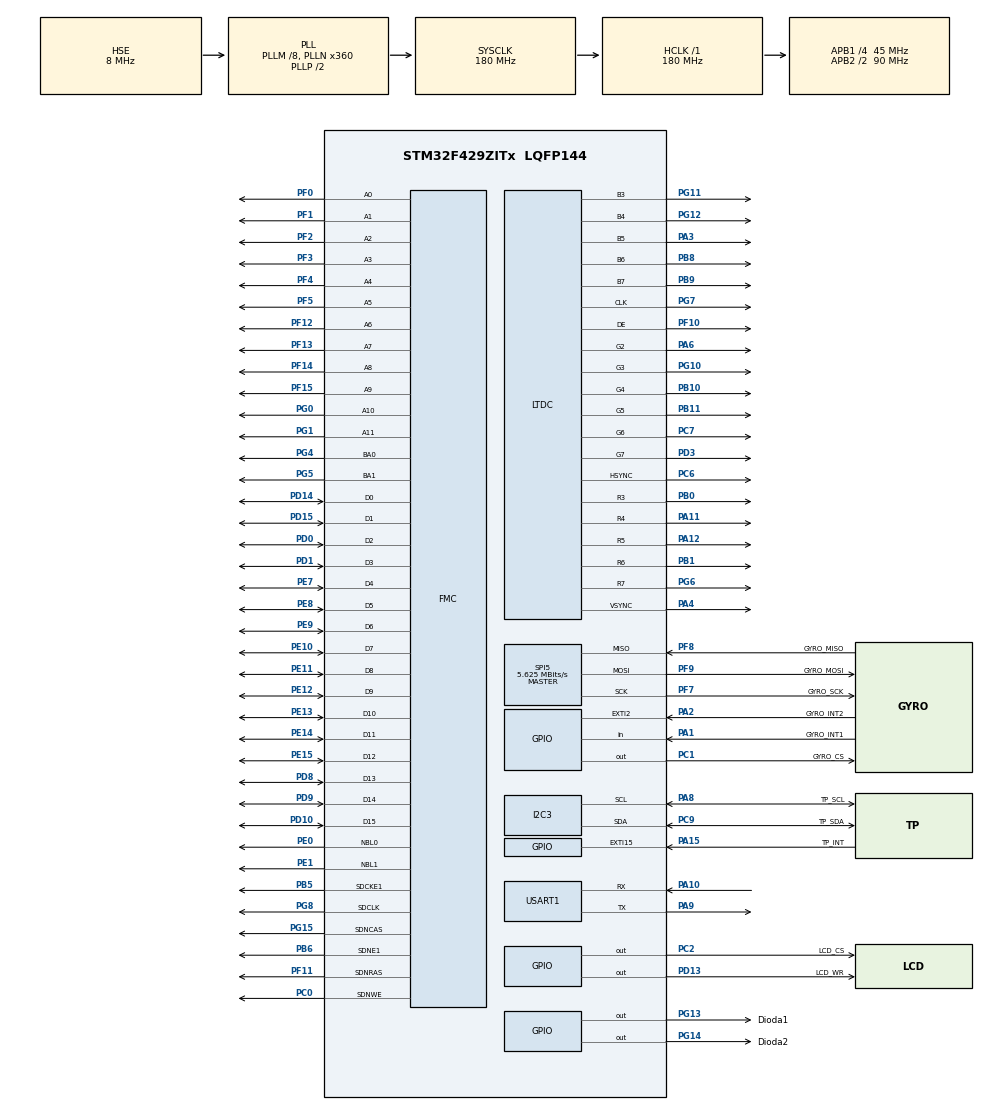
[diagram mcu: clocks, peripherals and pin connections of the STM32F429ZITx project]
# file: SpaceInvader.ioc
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DMA2D.ColorMode=DMA2D_OUTPUT_ARGB8888
DMA2D.Mode=DMA2D_R2M
FMC.CASLatency1=FMC_SDRAM_CAS_LATENCY_3
FMC.ExitSelfRefreshDelay1=7
FMC.LoadToActiveDelay1=2
FMC.RCDDelay1=2
FMC.RPDelay1=2
FMC.RPDelay2=2
FMC.ReadPipeDelay1=FMC_SDRAM_RPIPE_DELAY_1
FMC.ReadPipeDelay2=FMC_SDRAM_RPIPE_DELAY_1
FMC.RowCycleDelay1=7
FMC.RowCycleDelay2=7
FMC.SDClockPeriod1=FMC_SDRAM_CLOCK_PERIOD_2
FMC.SDClockPeriod2=FMC_SDRAM_CLOCK_PERIOD_2
FMC.SelfRefreshTime1=4
FMC.WriteRecoveryTime1=3
I2C3.I2C_Mode=I2C_Fast
LTDC.ActiveH=320
LTDC.ActiveW=240
LTDC.Alpha0_L0=0
LTDC.Alpha_L0=255
LTDC.BlendingFactor1_L0=LTDC_BLENDING_FACTOR1_PAxCA
LTDC.BlendingFactor2_L0=LTDC_BLENDING_FACTOR2_PAxCA
LTDC.FBStartAdress_L0=0xD0000000
LTDC.FBStartAdress_L1=0xD0006000
LTDC.HBP=20
LTDC.HFP=10
LTDC.HSync=10
LTDC.ImageHeight_L0=320
LTDC.ImageHeight_L1=320
LTDC.ImageWidth_L0=240
LTDC.ImageWidth_L1=240
LTDC.Layers=0
LTDC.PixelFormat_L0=LTDC_PIXEL_FORMAT_ARGB8888
LTDC.VFP=4
LTDC.VSync=2
LTDC.WindowX1_L0=240
LTDC.WindowX1_L1=240
LTDC.WindowY1_L0=320
LTDC.WindowY1_L1=320
Mcu.Family=STM32F4
Mcu.Name=STM32F429ZITx
Mcu.Package=LQFP144
NVIC.EXTI15_10_IRQn=true\:0\:0\:false\:false\:true\:true\:true\:true
NVIC.EXTI2_IRQn=true\:0\:0\:false\:false\:true\:true\:true\:true
NVIC.I2C3_ER_IRQn=true\:0\:0\:false\:false\:true\:true\:true\:true
NVIC.I2C3_EV_IRQn=true\:0\:0\:false\:false\:true\:true\:true\:true
NVIC.PriorityGroup=NVIC_PRIORITYGROUP_4
NVIC.TIM6_DAC_IRQn=true\:0\:0\:false\:false\:true\:true\:true\:true
NVIC.USART1_IRQn=true\:0\:0\:false\:false\:true\:true\:true\:true
PA1.GPIO_Label=GYRO_INT1
PA1.Signal=GPIO_Input
PA10.Mode=Asynchronous
PA10.Signal=USART1_RX
PA11.Mode=RGB565
PA11.Signal=LTDC_R4
PA12.Mode=RGB565
PA12.Signal=LTDC_R5
PA15.GPIO_Label=TP_INT
PA15.GPIO_ModeDefaultEXTI=GPIO_MODE_IT_FALLING
PA15.GPIO_PuPd=GPIO_PULLUP
PA15.Signal=GPXTI15
PA2.GPIO_Label=GYRO_INT2
PA2.GPIO_ModeDefaultEXTI=GPIO_MODE_IT_RISING_FALLING
PA2.Signal=GPXTI2
PA3.Mode=RGB565
PA3.Signal=LTDC_B5
PA4.Mode=RGB565
PA4.Signal=LTDC_VSYNC
PA6.Mode=RGB565
PA6.Signal=LTDC_G2
PA8.GPIO_Label=TP_SCL
PA8.Mode=I2C
PA8.Signal=I2C3_SCL
PA9.Mode=Asynchronous
PA9.Signal=USART1_TX
PB0.Mode=RGB565
PB0.Signal=LTDC_R3
PB1.Mode=RGB565
PB1.Signal=LTDC_R6
PB10.Mode=RGB565
PB10.Signal=LTDC_G4
PB11.Mode=RGB565
PB11.Signal=LTDC_G5
PB5.Mode=SdramChipSelect2_1
PB5.Signal=FMC_SDCKE1
PB6.Mode=SdramChipSelect2_1
PB6.Signal=FMC_SDNE1
PB8.Mode=RGB565
PB8.Signal=LTDC_B6
PB9.Mode=RGB565
PB9.Signal=LTDC_B7
PC0.Signal=FMC_SDNWE
PC1.GPIO_Label=GYRO_CS
PC1.PinState=GPIO_PIN_SET
PC1.Signal=GPIO_Output
PC14/OSC32_IN.GPIO_Label=OSC_IN
PC14/OSC32_IN.Signal=RCC_OSC32_IN
PC15/OSC32_OUT.GPIO_Label=OSC_OUT
PC15/OSC32_OUT.Signal=RCC_OSC32_OUT
PC2.GPIO_Label=LCD_CS
PC2.PinState=GPIO_PIN_SET
PC2.Signal=GPIO_Output
PC6.Mode=RGB565
PC6.Signal=LTDC_HSYNC
PC7.Mode=RGB565
PC7.Signal=LTDC_G6
PC9.GPIO_Label=TP_SDA
PC9.Mode=I2C
PC9.Signal=I2C3_SDA
PD0.Signal=FMC_D2_DA2
PD1.Signal=FMC_D3_DA3
PD10.Signal=FMC_D15_DA15
PD13.GPIO_Label=LCD_WR
PD13.Signal=GPIO_Output
PD14.Signal=FMC_D0_DA0
PD15.Signal=FMC_D1_DA1
PD3.Mode=RGB565
PD3.Signal=LTDC_G7
PD8.Signal=FMC_D13_DA13
PD9.Signal=FMC_D14_DA14
PE0.Signal=FMC_NBL0
PE1.Signal=FMC_NBL1
PE10.Signal=FMC_D7_DA7
PE11.Signal=FMC_D8_DA8
PE12.Signal=FMC_D9_DA9
PE13.Signal=FMC_D10_DA10
PE14.Signal=FMC_D11_DA11
PE15.Signal=FMC_D12_DA12
PE7.Signal=FMC_D4_DA4
PE8.Signal=FMC_D5_DA5
PE9.Signal=FMC_D6_DA6
PF0.Signal=FMC_A0
PF1.Signal=FMC_A1
PF10.Mode=RGB565
PF10.Signal=LTDC_DE
PF11.Signal=FMC_SDNRAS
PF12.Signal=FMC_A6
PF13.Signal=FMC_A7
PF14.Signal=FMC_A8
PF15.Signal=FMC_A9
PF2.Signal=FMC_A2
PF3.Signal=FMC_A3
PF4.Signal=FMC_A4
PF5.Signal=FMC_A5
PF7.GPIO_Label=GYRO_SCK
PF7.Mode=Full_Duplex_Master
PF7.Signal=SPI5_SCK
PF8.GPIO_Label=GYRO_MISO
PF8.Mode=Full_Duplex_Master
PF8.Signal=SPI5_MISO
PF9.GPIO_Label=GYRO_MOSI
PF9.Mode=Full_Duplex_Master
PF9.Signal=SPI5_MOSI
PG0.Signal=FMC_A10
PG1.Signal=FMC_A11
PG10.Mode=RGB565
PG10.Signal=LTDC_G3
PG11.Mode=RGB565
PG11.Signal=LTDC_B3
PG12.Mode=RGB565
PG12.Signal=LTDC_B4
PG13.GPIO_Label=Dioda1
PG13.Signal=GPIO_Output
PG14.GPIO_Label=Dioda2
PG14.Signal=GPIO_Output
PG15.Signal=FMC_SDNCAS
PG4.Signal=FMC_A14_BA0
PG5.Signal=FMC_A15_BA1
PG6.Mode=RGB565
PG6.Signal=LTDC_R7
PG7.Mode=RGB565
PG7.Signal=LTDC_CLK
PG8.Signal=FMC_SDCLK
PH0/OSC_IN.Mode=HSE-External-Oscillator
PH0/OSC_IN.Signal=RCC_OSC_IN
PH1/OSC_OUT.Mode=HSE-External-Oscillator
PH1/OSC_OUT.Signal=RCC_OSC_OUT
ProjectManager.HeapSize=0x200
ProjectManager.StackSize=0x400
ProjectManager.TargetToolchain=STM32CubeIDE
RCC.48MHZClocksFreq_Value=90000000
RCC.AHBFreq_Value=180000000
RCC.APB1CLKDivider=RCC_HCLK_DIV4
RCC.APB1Freq_Value=45000000
RCC.APB1TimFreq_Value=90000000
RCC.APB2CLKDivider=RCC_HCLK_DIV2
RCC.APB2Freq_Value=90000000
RCC.APB2TimFreq_Value=180000000
RCC.CortexFreq_Value=180000000
RCC.HCLKFreq_Value=180000000
RCC.HSE_VALUE=8000000
RCC.HSICalibrationValue=8
RCC.HSI_VALUE=16000000
RCC.LSE_VALUE=32768
RCC.PLLM=8
RCC.PLLN=360
RCC.PLLSAIDivR=RCC_PLLSAIDIVR_8
RCC.PLLSAIN=192
RCC.PLLSAIR=4
RCC.PLLSourceVirtual=RCC_PLLSOURCE_HSE
RCC.SYSCLKFreq_VALUE=180000000
RCC.SYSCLKSource=RCC_SYSCLKSOURCE_PLLCLK
RCC.VCOOutputFreq_Value=360000000
SH.FMC_A0.0=FMC_A0,12b-sda1
SH.FMC_A1.0=FMC_A1,12b-sda1
SH.FMC_A10.0=FMC_A10,12b-sda1
SH.FMC_A11.0=FMC_A11,12b-sda1
SH.FMC_A14_BA0.0=FMC_BA0,FourSdramBanks1
SH.FMC_A15_BA1.0=FMC_BA1,FourSdramBanks1
SH.FMC_A2.0=FMC_A2,12b-sda1
SH.FMC_A3.0=FMC_A3,12b-sda1
SH.FMC_A4.0=FMC_A4,12b-sda1
SH.FMC_A5.0=FMC_A5,12b-sda1
SH.FMC_A6.0=FMC_A6,12b-sda1
SH.FMC_A7.0=FMC_A7,12b-sda1
SH.FMC_A8.0=FMC_A8,12b-sda1
SH.FMC_A9.0=FMC_A9,12b-sda1
SH.FMC_D0_DA0.0=FMC_D0,sd-16b-d1
SH.FMC_D10_DA10.0=FMC_D10,sd-16b-d1
SH.FMC_D11_DA11.0=FMC_D11,sd-16b-d1
SH.FMC_D12_DA12.0=FMC_D12,sd-16b-d1
SH.FMC_D13_DA13.0=FMC_D13,sd-16b-d1
SH.FMC_D14_DA14.0=FMC_D14,sd-16b-d1
SH.FMC_D15_DA15.0=FMC_D15,sd-16b-d1
SH.FMC_D1_DA1.0=FMC_D1,sd-16b-d1
SH.FMC_D2_DA2.0=FMC_D2,sd-16b-d1
SH.FMC_D3_DA3.0=FMC_D3,sd-16b-d1
SH.FMC_D4_DA4.0=FMC_D4,sd-16b-d1
SH.FMC_D5_DA5.0=FMC_D5,sd-16b-d1
SH.FMC_D6_DA6.0=FMC_D6,sd-16b-d1
SH.FMC_D7_DA7.0=FMC_D7,sd-16b-d1
SH.FMC_D8_DA8.0=FMC_D8,sd-16b-d1
SH.FMC_D9_DA9.0=FMC_D9,sd-16b-d1
SH.FMC_NBL0.0=FMC_NBL0,Sd2ByteEnable1
SH.FMC_NBL1.0=FMC_NBL1,Sd2ByteEnable1
SH.FMC_SDCLK.0=FMC_SDCLK,12b-sda1
SH.FMC_SDNCAS.0=FMC_SDNCAS,12b-sda1
SH.FMC_SDNRAS.0=FMC_SDNRAS,12b-sda1
SH.FMC_SDNWE.0=FMC_SDNWE,12b-sda1
SPI5.BaudRatePrescaler=SPI_BAUDRATEPRESCALER_16
SPI5.CalculateBaudRate=5.625 MBits/s
SPI5.DataSize=SPI_DATASIZE_8BIT
SPI5.Direction=SPI_DIRECTION_2LINES
SPI5.Mode=SPI_MODE_MASTER
SPI5.VirtualType=VM_MASTER
TIM6.Period=99
TIM6.Prescaler=8999
USART1.VirtualMode=VM_ASYNC
VP_DMA2D_VS_DMA2D.Mode=DMA2D_Activate
VP_TIM6_VS_ClockSourceINT.Mode=Enable_Timer
board=custom

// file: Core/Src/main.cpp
/* USER CODE BEGIN Header */
/**
  ******************************************************************************
  * @file           : main.c
  * @brief          : Main program body
  ******************************************************************************
  * @attention
  *
  * Copyright (c) 2025 STMicroelectronics.
  * All rights reserved.
  *
  * This software is licensed under terms that can be found in the LICENSE file
  * in the root directory of this software component.
  * If no LICENSE file comes with this software, it is provided AS-IS.
  *
  ******************************************************************************
  */
/* USER CODE END Header */
#include <game_manager.hh>
extern "C"{
#include "main.h"
/* USER CODE BEGIN Includes */
#include "stdio.h"
#include "stdlib.h"
#include "drawFunctions.h"
#include "lcd.h"
#include "gyroscope.h"
#include "touch_panel.h"
#include "sram.h"
#include "gui.h"
/* USER CODE END Includes */

DMA2D_HandleTypeDef hdma2d;

I2C_HandleTypeDef hi2c3;

LTDC_HandleTypeDef hltdc;

SPI_HandleTypeDef hspi5;

TIM_HandleTypeDef htim6;

UART_HandleTypeDef huart1;

SDRAM_HandleTypeDef hsdram1;

/* USER CODE BEGIN PV */
uint32_t CURRENT_BUFFER=FRAMEBUFF_1;
uint32_t CURRENT_BUFFER_END=FRAMEBUFF_1_END;
uint32_t CURRENT_BACK_BUFFER=FRAMEBUFF_2;
uint32_t CURRENT_BACK_BUFFER_END=FRAMEBUFF_2_END;

bool textCenter=false;
volatile int TouchDetected=0;
volatile int RotDetected=0;
MenuState State=MENU;
int points=0;
int record=0;
bool isWon=false;
/* USER CODE END PV */

void SystemClock_Config(void);
static void MX_GPIO_Init(void);
static void MX_SPI5_Init(void);
static void MX_LTDC_Init(void);
static void MX_FMC_Init(void);
static void MX_DMA2D_Init(void);
static void MX_I2C3_Init(void);
static void MX_USART1_UART_Init(void);
static void MX_TIM6_Init(void);
/* USER CODE BEGIN PFP */
int _write(int, char *, int);
/* USER CODE END PFP */

/* USER CODE BEGIN 0 */
void HAL_GPIO_EXTI_Callback(uint16_t GPIO_Pin)
{
	if (GPIO_Pin == TP_INT_Pin)
	{
		TouchDetected=1;
	}
	if (GPIO_Pin == GYRO_INT2_Pin)
	{
		RotDetected=1;
	}
}
/* USER CODE END 0 */

/**
  * @brief  The application entry point.
  * @retval int
  */}
int main(void)
{

  /* MCU Configuration--------------------------------------------------------*/

  /* Reset of all peripherals, Initializes the Flash interface and the Systick. */
  HAL_Init();

  /* Configure the system clock */
  SystemClock_Config();

  /* Initialize all configured peripherals */
  MX_GPIO_Init();
  MX_SPI5_Init();
  MX_LTDC_Init();
  MX_FMC_Init();
  MX_DMA2D_Init();
  MX_I2C3_Init();
  MX_USART1_UART_Init();
  MX_TIM6_Init();
  /* USER CODE BEGIN 2 */
  initGyro();
  initTouchPanel();
  //testSDRAM();
  calibrateGyro();
  /* USER CODE END 2 */

  /* Infinite loop */
  /* USER CODE BEGIN WHILE */
  while(1)
  {
	  if(State==MENU) operateMenu();

	  srand(HAL_GetTick());
	  if(State==GAME) operateGame();

	  if(State==END) operateEndMenu();
    /* USER CODE END WHILE */

  }
}

extern "C"
{
void SystemClock_Config(void)
{
  RCC_OscInitTypeDef RCC_OscInitStruct = {0};
  RCC_ClkInitTypeDef RCC_ClkInitStruct = {0};

  /** Configure the main internal regulator output voltage
  */
  __HAL_RCC_PWR_CLK_ENABLE();
  __HAL_PWR_VOLTAGESCALING_CONFIG(PWR_REGULATOR_VOLTAGE_SCALE1);

  /** Initializes the RCC Oscillators according to the specified parameters
  * in the RCC_OscInitTypeDef structure.
  */
  RCC_OscInitStruct.OscillatorType = RCC_OSCILLATORTYPE_HSE;
  RCC_OscInitStruct.HSEState = RCC_HSE_ON;
  RCC_OscInitStruct.PLL.PLLState = RCC_PLL_ON;
  RCC_OscInitStruct.PLL.PLLSource = RCC_PLLSOURCE_HSE;
  RCC_OscInitStruct.PLL.PLLM = 8;
  RCC_OscInitStruct.PLL.PLLN = 360;
  RCC_OscInitStruct.PLL.PLLP = RCC_PLLP_DIV2;
  RCC_OscInitStruct.PLL.PLLQ = 4;
  if (HAL_RCC_OscConfig(&RCC_OscInitStruct) != HAL_OK)
  {
    Error_Handler();
  }

  /** Activate the Over-Drive mode
  */
  if (HAL_PWREx_EnableOverDrive() != HAL_OK)
  {
    Error_Handler();
  }

  /** Initializes the CPU, AHB and APB buses clocks
  */
  RCC_ClkInitStruct.ClockType = RCC_CLOCKTYPE_HCLK|RCC_CLOCKTYPE_SYSCLK
                              |RCC_CLOCKTYPE_PCLK1|RCC_CLOCKTYPE_PCLK2;
  RCC_ClkInitStruct.SYSCLKSource = RCC_SYSCLKSOURCE_PLLCLK;
  RCC_ClkInitStruct.AHBCLKDivider = RCC_SYSCLK_DIV1;
  RCC_ClkInitStruct.APB1CLKDivider = RCC_HCLK_DIV4;
  RCC_ClkInitStruct.APB2CLKDivider = RCC_HCLK_DIV2;

  if (HAL_RCC_ClockConfig(&RCC_ClkInitStruct, FLASH_LATENCY_5) != HAL_OK)
  {
    Error_Handler();
  }
}

static void MX_DMA2D_Init(void)
{

  hdma2d.Instance = DMA2D;
  hdma2d.Init.Mode = DMA2D_R2M;
  hdma2d.Init.ColorMode = DMA2D_OUTPUT_ARGB8888;
  hdma2d.Init.OutputOffset = 0;
  if (HAL_DMA2D_Init(&hdma2d) != HAL_OK)
  {
    Error_Handler();
  }
  /* USER CODE BEGIN DMA2D_Init 2 */
  // Konfiguracja warstwy tła
  hdma2d.LayerCfg[0].AlphaMode = DMA2D_NO_MODIF_ALPHA;
  hdma2d.LayerCfg[0].InputColorMode = DMA2D_INPUT_ARGB8888;
  HAL_DMA2D_ConfigLayer(&hdma2d, 0);
  // Konfiguracja warstwy ktora będzie nadpisywana z blendowaniem
  hdma2d.LayerCfg[1].AlphaMode = DMA2D_NO_MODIF_ALPHA;
  hdma2d.LayerCfg[1].InputColorMode = DMA2D_INPUT_ARGB8888;
  hdma2d.LayerCfg[1].InputOffset = 0;
  HAL_DMA2D_ConfigLayer(&hdma2d, 1);
  setBackgroundColor(0xFF000000);
  /* USER CODE END DMA2D_Init 2 */

}

static void MX_I2C3_Init(void)
{

  hi2c3.Instance = I2C3;
  hi2c3.Init.ClockSpeed = 400000;
  hi2c3.Init.DutyCycle = I2C_DUTYCYCLE_2;
  hi2c3.Init.OwnAddress1 = 0;
  hi2c3.Init.AddressingMode = I2C_ADDRESSINGMODE_7BIT;
  hi2c3.Init.DualAddressMode = I2C_DUALADDRESS_DISABLE;
  hi2c3.Init.OwnAddress2 = 0;
  hi2c3.Init.GeneralCallMode = I2C_GENERALCALL_DISABLE;
  hi2c3.Init.NoStretchMode = I2C_NOSTRETCH_DISABLE;
  if (HAL_I2C_Init(&hi2c3) != HAL_OK)
  {
    Error_Handler();
  }

  /** Configure Analogue filter
  */
  if (HAL_I2CEx_ConfigAnalogFilter(&hi2c3, I2C_ANALOGFILTER_ENABLE) != HAL_OK)
  {
    Error_Handler();
  }

  /** Configure Digital filter
  */
  if (HAL_I2CEx_ConfigDigitalFilter(&hi2c3, 0) != HAL_OK)
  {
    Error_Handler();
  }

}

static void MX_LTDC_Init(void)
{

  /* USER CODE BEGIN LTDC_Init 0 */

  // Konfiguracja zegara LCD. Wartosc zalecana - 6 MHz
  RCC_PeriphCLKInitTypeDef PeriphClkInitStruct = {0};

  /* F poczatkowa = 1 MHz */
  /* PLLSAIN step I = 1 Mhz * 192 = 192 Mhz */
  /* PLLSAIR step II = 192/4 = 48 Mhz */
  /* LTDC f koncowa = 48 / LTDC_PLLSAI_DIVR_8 = 48/8 = 6Mhz */
  PeriphClkInitStruct.PeriphClockSelection = RCC_PERIPHCLK_LTDC;
  PeriphClkInitStruct.PLLSAI.PLLSAIN = 192;
  PeriphClkInitStruct.PLLSAI.PLLSAIR = 4;
  PeriphClkInitStruct.PLLSAIDivR = RCC_PLLSAIDIVR_8;

  if (HAL_RCCEx_PeriphCLKConfig(&PeriphClkInitStruct) != HAL_OK)
  {
	  Error_Handler();
  }

  /* USER CODE END LTDC_Init 0 */

  LTDC_LayerCfgTypeDef pLayerCfg = {0};

  hltdc.Instance = LTDC;
  hltdc.Init.HSPolarity = LTDC_HSPOLARITY_AL;
  hltdc.Init.VSPolarity = LTDC_VSPOLARITY_AL;
  hltdc.Init.DEPolarity = LTDC_DEPOLARITY_AL;
  hltdc.Init.PCPolarity = LTDC_PCPOLARITY_IPC;
  hltdc.Init.HorizontalSync = 9;
  hltdc.Init.VerticalSync = 1;
  hltdc.Init.AccumulatedHBP = 29;
  hltdc.Init.AccumulatedVBP = 3;
  hltdc.Init.AccumulatedActiveW = 269;
  hltdc.Init.AccumulatedActiveH = 323;
  hltdc.Init.TotalWidth = 279;
  hltdc.Init.TotalHeigh = 327;
  hltdc.Init.Backcolor.Blue = 0;
  hltdc.Init.Backcolor.Green = 0;
  hltdc.Init.Backcolor.Red = 0;
  if (HAL_LTDC_Init(&hltdc) != HAL_OK)
  {
    Error_Handler();
  }
  pLayerCfg.WindowX0 = 0;
  pLayerCfg.WindowX1 = 240;
  pLayerCfg.WindowY0 = 0;
  pLayerCfg.WindowY1 = 320;
  pLayerCfg.PixelFormat = LTDC_PIXEL_FORMAT_ARGB8888;
  pLayerCfg.Alpha = 255;
  pLayerCfg.Alpha0 = 0;
  pLayerCfg.BlendingFactor1 = LTDC_BLENDING_FACTOR1_PAxCA;
  pLayerCfg.BlendingFactor2 = LTDC_BLENDING_FACTOR2_PAxCA;
  pLayerCfg.FBStartAdress = 0xD0000000;
  pLayerCfg.ImageWidth = 240;
  pLayerCfg.ImageHeight = 320;
  pLayerCfg.Backcolor.Blue = 0;
  pLayerCfg.Backcolor.Green = 0;
  pLayerCfg.Backcolor.Red = 0;
  if (HAL_LTDC_ConfigLayer(&hltdc, &pLayerCfg, 0) != HAL_OK)
  {
    Error_Handler();
  }
  /* USER CODE BEGIN LTDC_Init 2 */
  initLCD();
  /* USER CODE END LTDC_Init 2 */

}

static void MX_SPI5_Init(void)
{

  /* SPI5 parameter configuration*/
  hspi5.Instance = SPI5;
  hspi5.Init.Mode = SPI_MODE_MASTER;
  hspi5.Init.Direction = SPI_DIRECTION_2LINES;
  hspi5.Init.DataSize = SPI_DATASIZE_8BIT;
  hspi5.Init.CLKPolarity = SPI_POLARITY_LOW;
  hspi5.Init.CLKPhase = SPI_PHASE_1EDGE;
  hspi5.Init.NSS = SPI_NSS_SOFT;
  hspi5.Init.BaudRatePrescaler = SPI_BAUDRATEPRESCALER_16;
  hspi5.Init.FirstBit = SPI_FIRSTBIT_MSB;
  hspi5.Init.TIMode = SPI_TIMODE_DISABLE;
  hspi5.Init.CRCCalculation = SPI_CRCCALCULATION_DISABLE;
  hspi5.Init.CRCPolynomial = 10;
  if (HAL_SPI_Init(&hspi5) != HAL_OK)
  {
    Error_Handler();
  }

}

static void MX_TIM6_Init(void)
{

	  TIM_MasterConfigTypeDef sMasterConfig = {0};

	  htim6.Instance = TIM6;
	  htim6.Init.Prescaler = 8999;
	  htim6.Init.CounterMode = TIM_COUNTERMODE_UP;
	  htim6.Init.Period = 99;
	  htim6.Init.AutoReloadPreload = TIM_AUTORELOAD_PRELOAD_DISABLE;
	  if (HAL_TIM_Base_Init(&htim6) != HAL_OK)
	  {
	    Error_Handler();
	  }
	  sMasterConfig.MasterOutputTrigger = TIM_TRGO_RESET;
	  sMasterConfig.MasterSlaveMode = TIM_MASTERSLAVEMODE_DISABLE;
	  if (HAL_TIMEx_MasterConfigSynchronization(&htim6, &sMasterConfig) != HAL_OK)
	  {
	    Error_Handler();
	  }

}

static void MX_USART1_UART_Init(void)
{

  huart1.Instance = USART1;
  huart1.Init.BaudRate = 115200;
  huart1.Init.WordLength = UART_WORDLENGTH_8B;
  huart1.Init.StopBits = UART_STOPBITS_1;
  huart1.Init.Parity = UART_PARITY_NONE;
  huart1.Init.Mode = UART_MODE_TX_RX;
  huart1.Init.HwFlowCtl = UART_HWCONTROL_NONE;
  huart1.Init.OverSampling = UART_OVERSAMPLING_16;
  if (HAL_UART_Init(&huart1) != HAL_OK)
  {
    Error_Handler();
  }

}

/* FMC initialization function */
static void MX_FMC_Init(void)
{

  FMC_SDRAM_TimingTypeDef SdramTiming = {0};

  /** Perform the SDRAM1 memory initialization sequence
  */
  hsdram1.Instance = FMC_SDRAM_DEVICE;
  /* hsdram1.Init */
  hsdram1.Init.SDBank = FMC_SDRAM_BANK2;
  hsdram1.Init.ColumnBitsNumber = FMC_SDRAM_COLUMN_BITS_NUM_8;
  hsdram1.Init.RowBitsNumber = FMC_SDRAM_ROW_BITS_NUM_12;
  hsdram1.Init.MemoryDataWidth = FMC_SDRAM_MEM_BUS_WIDTH_16;
  hsdram1.Init.InternalBankNumber = FMC_SDRAM_INTERN_BANKS_NUM_4;
  hsdram1.Init.CASLatency = FMC_SDRAM_CAS_LATENCY_3;
  hsdram1.Init.WriteProtection = FMC_SDRAM_WRITE_PROTECTION_DISABLE;
  hsdram1.Init.SDClockPeriod = FMC_SDRAM_CLOCK_PERIOD_2;
  hsdram1.Init.ReadBurst = FMC_SDRAM_RBURST_DISABLE;
  hsdram1.Init.ReadPipeDelay = FMC_SDRAM_RPIPE_DELAY_1;
  /* SdramTiming */
  SdramTiming.LoadToActiveDelay = 2;
  SdramTiming.ExitSelfRefreshDelay = 7;
  SdramTiming.SelfRefreshTime = 4;
  SdramTiming.RowCycleDelay = 7;
  SdramTiming.WriteRecoveryTime = 3;
  SdramTiming.RPDelay = 2;
  SdramTiming.RCDDelay = 2;

  if (HAL_SDRAM_Init(&hsdram1, &SdramTiming) != HAL_OK)
  {
    Error_Handler( );
  }

  /* USER CODE BEGIN FMC_Init 2 */
  initSDRAM(&hsdram1);
  /* USER CODE END FMC_Init 2 */
}

static void MX_GPIO_Init(void)
{
  GPIO_InitTypeDef GPIO_InitStruct = {0};

  /* GPIO Ports Clock Enable */
  __HAL_RCC_GPIOC_CLK_ENABLE();
  __HAL_RCC_GPIOF_CLK_ENABLE();
  __HAL_RCC_GPIOH_CLK_ENABLE();
  __HAL_RCC_GPIOA_CLK_ENABLE();
  __HAL_RCC_GPIOB_CLK_ENABLE();
  __HAL_RCC_GPIOG_CLK_ENABLE();
  __HAL_RCC_GPIOE_CLK_ENABLE();
  __HAL_RCC_GPIOD_CLK_ENABLE();

  /*Configure GPIO pin Output Level */
  HAL_GPIO_WritePin(GPIOC, GYRO_CS_Pin|LCD_CS_Pin, GPIO_PIN_SET);

  /*Configure GPIO pin Output Level */
  HAL_GPIO_WritePin(LCD_WR_GPIO_Port, LCD_WR_Pin, GPIO_PIN_RESET);

  /*Configure GPIO pin Output Level */
  HAL_GPIO_WritePin(GPIOG, Dioda1_Pin|Dioda2_Pin, GPIO_PIN_RESET);

  /*Configure GPIO pins : GYRO_CS_Pin LCD_CS_Pin */
  GPIO_InitStruct.Pin = GYRO_CS_Pin|LCD_CS_Pin;
  GPIO_InitStruct.Mode = GPIO_MODE_OUTPUT_PP;
  GPIO_InitStruct.Pull = GPIO_NOPULL;
  GPIO_InitStruct.Speed = GPIO_SPEED_FREQ_LOW;
  HAL_GPIO_Init(GPIOC, &GPIO_InitStruct);

  /*Configure GPIO pin : GYRO_INT1_Pin */
  GPIO_InitStruct.Pin = GYRO_INT1_Pin;
  GPIO_InitStruct.Mode = GPIO_MODE_INPUT;
  GPIO_InitStruct.Pull = GPIO_NOPULL;
  HAL_GPIO_Init(GYRO_INT1_GPIO_Port, &GPIO_InitStruct);

  /*Configure GPIO pin : GYRO_INT2_Pin */
  GPIO_InitStruct.Pin = GYRO_INT2_Pin;
  GPIO_InitStruct.Mode = GPIO_MODE_IT_RISING_FALLING;
  GPIO_InitStruct.Pull = GPIO_NOPULL;
  HAL_GPIO_Init(GYRO_INT2_GPIO_Port, &GPIO_InitStruct);

  /*Configure GPIO pin : LCD_WR_Pin */
  GPIO_InitStruct.Pin = LCD_WR_Pin;
  GPIO_InitStruct.Mode = GPIO_MODE_OUTPUT_PP;
  GPIO_InitStruct.Pull = GPIO_NOPULL;
  GPIO_InitStruct.Speed = GPIO_SPEED_FREQ_LOW;
  HAL_GPIO_Init(LCD_WR_GPIO_Port, &GPIO_InitStruct);

  /*Configure GPIO pin : TP_INT_Pin */
  GPIO_InitStruct.Pin = TP_INT_Pin;
  GPIO_InitStruct.Mode = GPIO_MODE_IT_FALLING;
  GPIO_InitStruct.Pull = GPIO_PULLUP;
  HAL_GPIO_Init(TP_INT_GPIO_Port, &GPIO_InitStruct);

  /*Configure GPIO pins : Dioda1_Pin Dioda2_Pin */
  GPIO_InitStruct.Pin = Dioda1_Pin|Dioda2_Pin;
  GPIO_InitStruct.Mode = GPIO_MODE_OUTPUT_PP;
  GPIO_InitStruct.Pull = GPIO_NOPULL;
  GPIO_InitStruct.Speed = GPIO_SPEED_FREQ_LOW;
  HAL_GPIO_Init(GPIOG, &GPIO_InitStruct);

  /* EXTI interrupt init*/
  HAL_NVIC_SetPriority(EXTI2_IRQn, 0, 0);
  HAL_NVIC_EnableIRQ(EXTI2_IRQn);

  HAL_NVIC_SetPriority(EXTI15_10_IRQn, 0, 0);
  HAL_NVIC_EnableIRQ(EXTI15_10_IRQn);

}

/* USER CODE BEGIN 4 */

int _write(int file, char *ptr, int len)
{
	HAL_UART_Transmit(&huart1, (uint8_t*) ptr, len, HAL_MAX_DELAY);
	return len;
}

/* USER CODE END 4 */

void Error_Handler(void)
{
  __disable_irq();
  while (1)
  {
  }
}
}
